# ESP32-C5 register map
Vendor: ESPRESSIF SYSTEMS (SHANGHAI) CO., LTD.; Series: ESP32 C-Series; File version: 1
CPU: RV32IMAC r0p0, little endian, no MPU, no FPU, 0 interrupt priority bits
Address unit: 32 bits
Registers are 32-bit, read-write, reset 0x0 unless marked. A register's access mark holds for its fields unless they carry their own. Offsets are from the block's base; [hi:lo] are bit positions; {n}, {i} and the like mark numbered series.

## EFUSE — eFuse Controller
Base 0x600B4800
{0x0+4i} PGM_DATA{i} (i=0..7) — Represents pgm_data{i}
  [31:0] PGM_DATA — Configures the %sth 32-bit data to be programmed.
{0x20+4i} PGM_CHECK_VALUE{i} (i=0..2) — Represents pgm_check_value{i}
  [31:0] PGM_RS_DATA — Configures the %sth RS code to be programmed.
0x2C RD_WR_DIS0 ro — Represents rd_wr_dis
  [31:0] WR_DIS — Represents whether programming of individual eFuse memory bit is disabled or enabled.\\ 1: Disabled\\ 0: Enabled\\
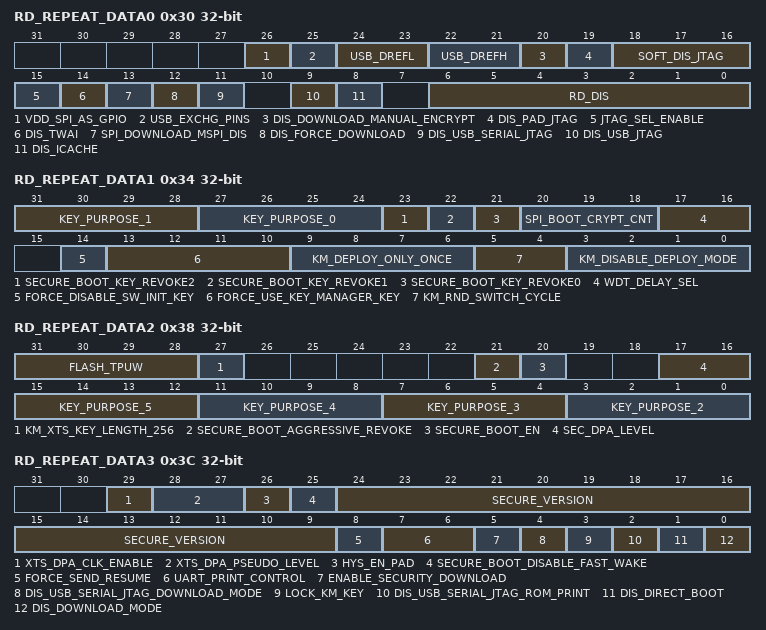
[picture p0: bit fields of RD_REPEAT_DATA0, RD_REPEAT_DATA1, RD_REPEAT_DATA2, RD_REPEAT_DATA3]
0x30 RD_REPEAT_DATA0 ro — Represents rd_repeat_data
  [26] VDD_SPI_AS_GPIO — Represents whether vdd spi pin is functioned as gpio.\\ 1: functioned\\ 0: not functioned\\
  [25] USB_EXCHG_PINS — Represents whether the D+ and D- pins is exchanged.\\ 1: exchanged\\ 0: not exchanged\\
  [24:23] USB_DREFL — Represents the single-end input threhold vrefl, 1.76 V to 2 V with step of 80 mV.
  [22:21] USB_DREFH — Represents the single-end input threhold vrefh, 1.76 V to 2 V with step of 80 mV.
  [20] DIS_DOWNLOAD_MANUAL_ENCRYPT — Represents whether flash encrypt function is disabled or enabled(except in SPI boot mode).\\ 1: disabled\\ 0: enabled\\
  [19] DIS_PAD_JTAG — Represents whether JTAG is disabled in the hard way(permanently).\\ 1: disabled\\ 0: enabled\\
  [18:16] SOFT_DIS_JTAG — Represents whether JTAG is disabled in soft way.\\ Odd number: disabled\\ Even number: enabled\\
  [15] JTAG_SEL_ENABLE — Represents whether the selection between usb_to_jtag and pad_to_jtag through strapping gpio15 when both EFUSE_DIS_PAD_JTAG and EFUSE_DIS_USB_JTAG are equal to 0 is enabled or disabled.\\ 1: enabled\\ 0: disabled\\
  [14] DIS_TWAI — Represents whether TWAI function is disabled or enabled.\\ 1: disabled\\ 0: enabled\\
  [13] SPI_DOWNLOAD_MSPI_DIS — Represents whether SPI0 controller during boot_mode_download is disabled or enabled.\\ 1: disabled\\ 0: enabled\\
  [12] DIS_FORCE_DOWNLOAD — Represents whether the function that forces chip into download mode is disabled or enabled.\\ 1: disabled\\ 0: enabled\\
  [11] DIS_USB_SERIAL_JTAG — Represents whether USB-Serial-JTAG is disabled or enabled.\\ 1: disabled\\ 0: enabled\\
  [9] DIS_USB_JTAG — Represents whether the function of usb switch to jtag is disabled or enabled.\\ 1: disabled\\ 0: enabled\\
  [8] DIS_ICACHE — Represents whether icache is disabled or enabled.\\ 1: disabled\\ 0: enabled\\
  [6:0] RD_DIS — Represents whether reading of individual eFuse block(block4~block10) is disabled or enabled.\\ 1: disabled\\ 0: enabled\\
0x34 RD_REPEAT_DATA1 ro — Represents rd_repeat_data
  [31:28] KEY_PURPOSE_1 — Represents the purpose of Key1.
  [27:24] KEY_PURPOSE_0 — Represents the purpose of Key0.
  [23] SECURE_BOOT_KEY_REVOKE2 — Represents whether revoking third secure boot key is enabled or disabled.\\ 1: enabled\\ 0: disabled\\
  [22] SECURE_BOOT_KEY_REVOKE1 — Represents whether revoking second secure boot key is enabled or disabled.\\ 1: enabled\\ 0: disabled\\
  [21] SECURE_BOOT_KEY_REVOKE0 — Represents whether revoking first secure boot key is enabled or disabled.\\ 1: enabled\\ 0: disabled\\
  [20:18] SPI_BOOT_CRYPT_CNT — Represents whether SPI boot encrypt/decrypt is disabled or enabled.\\ Odd number of 1: enabled\\ Even number of 1: disabled\\
  [17:16] WDT_DELAY_SEL — Represents the threshold level of the RTC watchdog STG0 timeout.\\ 0: Original threshold configuration value of STG0 *2 \\1: Original threshold configuration value of STG0 *4 \\2: Original threshold configuration value of STG0 *8 \\3: Original threshold configuration value of STG0 *16 \\
  [14] FORCE_DISABLE_SW_INIT_KEY — Set this bit to disable software written init key, and force use efuse_init_key.
  [13:10] FORCE_USE_KEY_MANAGER_KEY — Set each bit to control whether corresponding key must come from key manager. 1 is true, 0 is false. bit 0: ecsda, bit 1: xts, bit2: hmac, bit3: ds
  [9:6] KM_DEPLOY_ONLY_ONCE — Set each bit to control whether corresponding key can only be deployed once. 1 is true, 0 is false. bit 0: ecsda, bit 1: xts, bit2: hmac, bit3: ds
  [5:4] KM_RND_SWITCH_CYCLE — Set the bits to control key manager random number switch cycle. 0: control by register. 1: 8 km clk cycles. 2: 16 km cycles. 3: 32 km cycles
  [3:0] KM_DISABLE_DEPLOY_MODE — Represents whether the deploy mode of key manager is disable or not. \\ 1: disabled \\ 0: enabled.\\
0x38 RD_REPEAT_DATA2 ro — Represents rd_repeat_data
  [31:28] FLASH_TPUW — Represents the flash waiting time after power-up, in unit of ms. When the value less than 15, the waiting time is the programmed value. Otherwise, the waiting time is 2 times the programmed value.
  [27] KM_XTS_KEY_LENGTH_256 — Set this bitto configure flash encryption use xts-128 key. else use xts-256 key.
  [21] SECURE_BOOT_AGGRESSIVE_REVOKE — Represents whether revoking aggressive secure boot is enabled or disabled.\\ 1: enabled.\\ 0: disabled\\
  [20] SECURE_BOOT_EN — Represents whether secure boot is enabled or disabled.\\ 1: enabled\\ 0: disabled\\
  [17:16] SEC_DPA_LEVEL — Represents the spa secure level by configuring the clock random divide mode.
  [4n-5:4n-8] KEY_PURPOSE_{n} (n=2..5) — Represents the purpose of Key{n}.
0x3C RD_REPEAT_DATA3 ro — Represents rd_repeat_data
  [29] XTS_DPA_CLK_ENABLE — Represents whether xts-aes anti-dpa attack clock is enabled.\\ 1. Enable.\\ 0: Disable.\\
  [28:27] XTS_DPA_PSEUDO_LEVEL — Represents the pseudo round level of xts-aes anti-dpa attack.\\ 3: High.\\ 2: Moderate 1. Low\\ 0: Disabled\\
  [26] HYS_EN_PAD — Represents whether the hysteresis function of corresponding PAD is enabled.\\ 1: enabled\\ 0:disabled\\
  [25] SECURE_BOOT_DISABLE_FAST_WAKE — Represents whether FAST VERIFY ON WAKE is disabled or enabled when Secure Boot is enabled.\\ 1: disabled\\ 0: enabled\\
  [24:9] SECURE_VERSION — Represents the version used by ESP-IDF anti-rollback feature.
  [8] FORCE_SEND_RESUME — Represents whether ROM code is forced to send a resume command during SPI boot.\\ 1: forced\\ 0:not forced\\
  [7:6] UART_PRINT_CONTROL — Represents the type of UART printing.\\ 00: force enable printing\\ 01: enable printing when GPIO8 is reset at low level\\ 10: enable printing when GPIO8 is reset at high level\\ 11: force disable printing\\
  [5] ENABLE_SECURITY_DOWNLOAD — Represents whether security download is enabled or disabled.\\ 1: enabled\\ 0: disabled\\
  [4] DIS_USB_SERIAL_JTAG_DOWNLOAD_MODE — Represents whether the USB-Serial-JTAG download function is disabled or enabled.\\ 1: Disable\\ 0: Enable\\
  [3] LOCK_KM_KEY — Represetns whether to lock the efuse xts key.\\ 1. Lock\\ 0: Unlock\\
  [2] DIS_USB_SERIAL_JTAG_ROM_PRINT — Represents whether print from USB-Serial-JTAG is disabled or enabled.\\ 1: disabled\\ 0: enabled\\
  [1] DIS_DIRECT_BOOT — Represents whether direct boot mode is disabled or enabled.\\ 1: disabled\\ 0: enabled\\
  [0] DIS_DOWNLOAD_MODE — Represents whether Download mode is disabled or enabled.\\ 1: disabled\\ 0: enabled\\
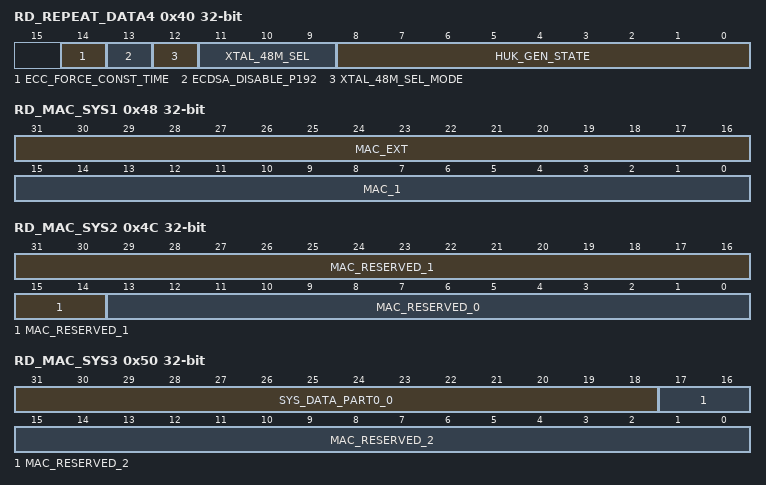
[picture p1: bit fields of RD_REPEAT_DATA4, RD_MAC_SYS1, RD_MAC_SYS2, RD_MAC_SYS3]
0x40 RD_REPEAT_DATA4 ro — Represents rd_repeat_data
  [14] ECC_FORCE_CONST_TIME — Represents whether to force ecc to use const-time calculation mode. \\ 1: Enable. \\ 0: Disable.
  [13] ECDSA_DISABLE_P192 — Represents whether to disable P192 curve in ECDSA.\\ 1: Disabled.\\ 0: Not disable.
  [12] XTAL_48M_SEL_MODE — Specify the XTAL frequency selection is decided by eFuse or strapping-PAD-state. 1: eFuse\\ 0: strapping-PAD-state.
  [11:9] XTAL_48M_SEL — Represents whether XTAL frequency is 48MHz or not. If not, 40MHz XTAL will be used. If this field contains Odd number bit '1': Enable 48MHz XTAL\\ Even number bit '1': Enable 40MHz XTAL.
  [8:0] HUK_GEN_STATE — Set the bits to control validation of HUK generate mode.\\ Odd of 1 is invalid.\\ Even of 1 is valid.\\
0x44 RD_MAC_SYS0 ro — Represents rd_mac_sys
  [31:0] MAC_0 — Represents MAC address. Low 32-bit.
0x48 RD_MAC_SYS1 ro — Represents rd_mac_sys
  [31:16] MAC_EXT — Represents the extended bits of MAC address.
  [15:0] MAC_1 — Represents MAC address. High 16-bit.
0x4C RD_MAC_SYS2 ro — Represents rd_mac_sys
  [31:14] MAC_RESERVED_1 — Reserved.
  [13:0] MAC_RESERVED_0 — Reserved.
0x50 RD_MAC_SYS3 ro — Represents rd_mac_sys
  [31:18] SYS_DATA_PART0_0 — Represents the first 14-bit of zeroth part of system data.
  [17:0] MAC_RESERVED_2 — Reserved.
0x54 RD_MAC_SYS4 ro — Represents rd_mac_sys
  [31:0] SYS_DATA_PART0_1 — Represents the first 14-bit of zeroth part of system data.
0x58 RD_MAC_SYS5 ro — Represents rd_mac_sys
  [31:0] SYS_DATA_PART0_2 — Represents the second 32-bit of zeroth part of system data.
{0x5C+4i} RD_SYS_PART1_DATA{i} (i=0..7) ro — Represents rd_sys_part1_data{i}
  [31:0] SYS_DATA_PART1 — Represents the zeroth 32-bit of first part of system data.
{0x7C+4i} RD_USR_DATA{i} (i=0..7) ro — Represents rd_usr_data{i}
  [31:0] USR_DATA — Represents the zeroth 32-bit of block3 (user).
{0x9C+4i} RD_KEY0_DATA{i} (i=0..7) ro — Represents rd_key0_data{i}
  [31:0] KEY0_DATA — Represents the zeroth 32-bit of key0.
{0xBC+4i} RD_KEY1_DATA{i} (i=0..7) ro — Represents rd_key1_data{i}
  [31:0] KEY1_DATA — Represents the zeroth 32-bit of key1.
{0xDC+4i} RD_KEY2_DATA{i} (i=0..7) ro — Represents rd_key2_data{i}
  [31:0] KEY2_DATA — Represents the zeroth 32-bit of key2.
{0xFC+4i} RD_KEY3_DATA{i} (i=0..7) ro — Represents rd_key3_data{i}
  [31:0] KEY3_DATA — Represents the zeroth 32-bit of key3.
{0x11C+4i} RD_KEY4_DATA{i} (i=0..7) ro — Represents rd_key4_data{i}
  [31:0] KEY4_DATA — Represents the zeroth 32-bit of key4.
{0x13C+4i} RD_KEY5_DATA{i} (i=0..7) ro — Represents rd_key5_data{i}
  [31:0] KEY5_DATA — Represents the zeroth 32-bit of key5.
{0x15C+4i} RD_SYS_PART2_DATA{i} (i=0..7) ro — Represents rd_sys_part2_data{i}
  [31:0] SYS_DATA_PART2 — Represents the zeroth 32-bit of second part of system data.
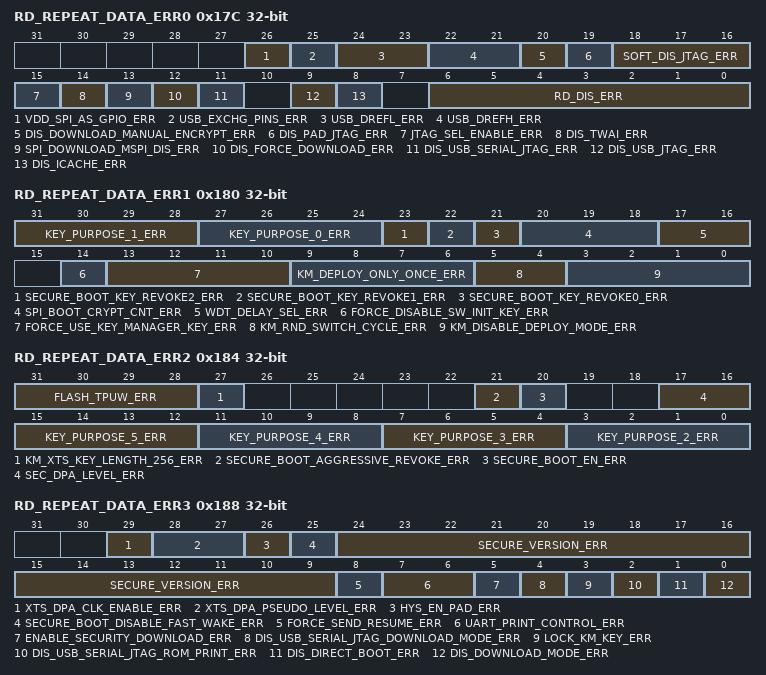
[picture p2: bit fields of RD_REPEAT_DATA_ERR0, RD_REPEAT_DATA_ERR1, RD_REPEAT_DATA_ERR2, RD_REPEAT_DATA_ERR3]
0x17C RD_REPEAT_DATA_ERR0 ro — Represents rd_repeat_data_err
  [26] VDD_SPI_AS_GPIO_ERR — Represents the programming error of EFUSE_VDD_SPI_AS_GPIO
  [25] USB_EXCHG_PINS_ERR — Represents the programming error of EFUSE_USB_EXCHG_PINS
  [24:23] USB_DREFL_ERR — Represents the programming error of EFUSE_USB_DREFL
  [22:21] USB_DREFH_ERR — Represents the programming error of EFUSE_USB_DREFH
  [20] DIS_DOWNLOAD_MANUAL_ENCRYPT_ERR — Represents the programming error of EFUSE_DIS_DOWNLOAD_MANUAL_ENCRYPT
  [19] DIS_PAD_JTAG_ERR — Represents the programming error of EFUSE_DIS_PAD_JTAG
  [18:16] SOFT_DIS_JTAG_ERR — Represents the programming error of EFUSE_SOFT_DIS_JTAG
  [15] JTAG_SEL_ENABLE_ERR — Represents the programming error of EFUSE_JTAG_SEL_ENABLE
  [14] DIS_TWAI_ERR — Represents the programming error of EFUSE_DIS_TWAI
  [13] SPI_DOWNLOAD_MSPI_DIS_ERR — Represents the programming error of EFUSE_SPI_DOWNLOAD_MSPI_DIS
  [12] DIS_FORCE_DOWNLOAD_ERR — Represents the programming error of EFUSE_DIS_FORCE_DOWNLOAD
  [11] DIS_USB_SERIAL_JTAG_ERR — Represents the programming error of EFUSE_DIS_USB_SERIAL_JTAG
  [9] DIS_USB_JTAG_ERR — Represents the programming error of EFUSE_DIS_USB_JTAG
  [8] DIS_ICACHE_ERR — Represents the programming error of EFUSE_DIS_ICACHE
  [6:0] RD_DIS_ERR — Represents the programming error of EFUSE_RD_DIS
0x180 RD_REPEAT_DATA_ERR1 ro — Represents rd_repeat_data_err
  [31:28] KEY_PURPOSE_1_ERR — Represents the programming error of EFUSE_KEY_PURPOSE_1
  [27:24] KEY_PURPOSE_0_ERR — Represents the programming error of EFUSE_KEY_PURPOSE_0
  [23] SECURE_BOOT_KEY_REVOKE2_ERR — Represents the programming error of EFUSE_SECURE_BOOT_KEY_REVOKE2
  [22] SECURE_BOOT_KEY_REVOKE1_ERR — Represents the programming error of EFUSE_SECURE_BOOT_KEY_REVOKE1
  [21] SECURE_BOOT_KEY_REVOKE0_ERR — Represents the programming error of EFUSE_SECURE_BOOT_KEY_REVOKE0
  [20:18] SPI_BOOT_CRYPT_CNT_ERR — Represents the programming error of EFUSE_SPI_BOOT_CRYPT_CNT
  [17:16] WDT_DELAY_SEL_ERR — Represents the programming error of EFUSE_WDT_DELAY_SEL
  [14] FORCE_DISABLE_SW_INIT_KEY_ERR — Represents the programming error of EFUSE_FORCE_DISABLE_SW_INIT_KEY
  [13:10] FORCE_USE_KEY_MANAGER_KEY_ERR — Represents the programming error of EFUSE_FORCE_USE_KEY_MANAGER_KEY
  [9:6] KM_DEPLOY_ONLY_ONCE_ERR — Represents the programming error of EFUSE_KM_DEPLOY_ONLY_ONCE
  [5:4] KM_RND_SWITCH_CYCLE_ERR — Represents the programming error of EFUSE_KM_RND_SWITCH_CYCLE
  [3:0] KM_DISABLE_DEPLOY_MODE_ERR — Represents the programming error of EFUSE_KM_DISABLE_DEPLOY_MODE
0x184 RD_REPEAT_DATA_ERR2 ro — Represents rd_repeat_data_err
  [31:28] FLASH_TPUW_ERR — Represents the programming error of EFUSE_FLASH_TPUW
  [27] KM_XTS_KEY_LENGTH_256_ERR — Represents the programming error of EFUSE_KM_XTS_KEY_LENGTH_256
  [21] SECURE_BOOT_AGGRESSIVE_REVOKE_ERR — Represents the programming error of EFUSE_SECURE_BOOT_AGGRESSIVE_REVOKE
  [20] SECURE_BOOT_EN_ERR — Represents the programming error of EFUSE_SECURE_BOOT_EN
  [17:16] SEC_DPA_LEVEL_ERR — Represents the programming error of EFUSE_SEC_DPA_LEVEL
  [4n-5:4n-8] KEY_PURPOSE_{n}_ERR (n=2..5) — Represents the programming error of EFUSE_KEY_PURPOSE_{n}
0x188 RD_REPEAT_DATA_ERR3 ro — Represents rd_repeat_data_err
  [29] XTS_DPA_CLK_ENABLE_ERR — Represents the programming error of EFUSE_XTS_DPA_CLK_ENABLE
  [28:27] XTS_DPA_PSEUDO_LEVEL_ERR — Represents the programming error of EFUSE_XTS_DPA_PSEUDO_LEVEL
  [26] HYS_EN_PAD_ERR — Represents the programming error of EFUSE_HYS_EN_PAD
  [25] SECURE_BOOT_DISABLE_FAST_WAKE_ERR — Represents the programming error of EFUSE_SECURE_BOOT_DISABLE_FAST_WAKE
  [24:9] SECURE_VERSION_ERR — Represents the programming error of EFUSE_SECURE_VERSION
  [8] FORCE_SEND_RESUME_ERR — Represents the programming error of EFUSE_FORCE_SEND_RESUME
  [7:6] UART_PRINT_CONTROL_ERR — Represents the programming error of EFUSE_UART_PRINT_CONTROL
  [5] ENABLE_SECURITY_DOWNLOAD_ERR — Represents the programming error of EFUSE_ENABLE_SECURITY_DOWNLOAD
  [4] DIS_USB_SERIAL_JTAG_DOWNLOAD_MODE_ERR — Represents the programming error of EFUSE_DIS_USB_SERIAL_JTAG_DOWNLOAD_MODE
  [3] LOCK_KM_KEY_ERR — Represents the programming error of EFUSE_LOCK_KM_KEY
  [2] DIS_USB_SERIAL_JTAG_ROM_PRINT_ERR — Represents the programming error of EFUSE_DIS_USB_SERIAL_JTAG_ROM_PRINT
  [1] DIS_DIRECT_BOOT_ERR — Represents the programming error of EFUSE_DIS_DIRECT_BOOT
  [0] DIS_DOWNLOAD_MODE_ERR — Represents the programming error of EFUSE_DIS_DOWNLOAD_MODE
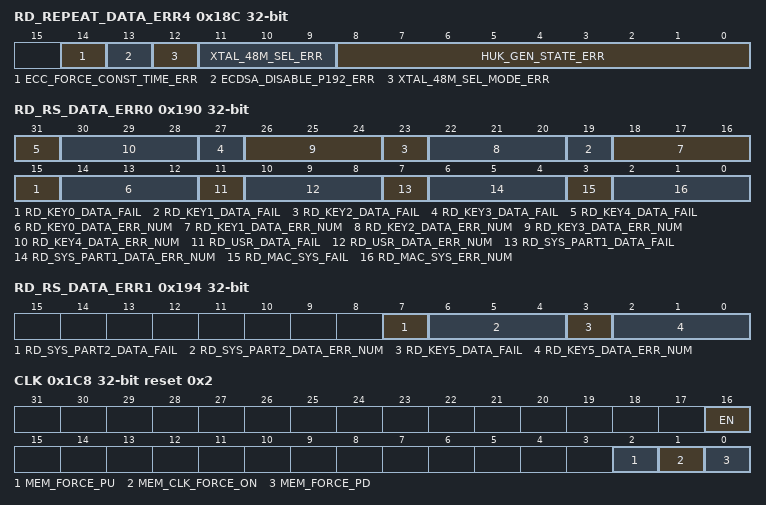
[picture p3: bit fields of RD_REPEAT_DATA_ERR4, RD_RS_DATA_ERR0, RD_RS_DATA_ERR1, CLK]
0x18C RD_REPEAT_DATA_ERR4 ro — Represents rd_repeat_data_err
  [14] ECC_FORCE_CONST_TIME_ERR — Represents the programming error of EFUSE_ECC_FORCE_CONST_TIME
  [13] ECDSA_DISABLE_P192_ERR — Represents the programming error of EFUSE_ECDSA_DISABLE_P192
  [12] XTAL_48M_SEL_MODE_ERR — Represents the programming error of EFUSE_XTAL_48M_SEL_MODE
  [11:9] XTAL_48M_SEL_ERR — Represents the programming error of EFUSE_XTAL_48M_SEL
  [8:0] HUK_GEN_STATE_ERR — Represents the programming error of EFUSE_HUK_GEN_STATE
0x190 RD_RS_DATA_ERR0 ro — Represents rd_rs_data_err
  [4n+15] RD_KEY{n}_DATA_FAIL (n=0..4) — Represents error status of register.\\0: Means no failure and that the data of rd_key{n}_data is reliable\\ 1: Means that programming rd_key{n}_data failed and the number of error bytes is over 6.
  [4n+14:4n+12] RD_KEY{n}_DATA_ERR_NUM (n=0..4) — Represents the error number of registers.\\The value of this signal means the number of error bytes in rd_key{n}_data
  [11] RD_USR_DATA_FAIL — Represents error status of register.\\0: Means no failure and that the data of rd_usr_data is reliable\\ 1: Means that programming rd_usr_data failed and the number of error bytes is over 6.
  [10:8] RD_USR_DATA_ERR_NUM — Represents the error number of registers.\\The value of this signal means the number of error bytes in rd_usr_data
  [7] RD_SYS_PART1_DATA_FAIL — Represents error status of register.\\0: Means no failure and that the data of rd_sys_part1_data is reliable\\ 1: Means that programming rd_sys_part1_data failed and the number of error bytes is over 6.
  [6:4] RD_SYS_PART1_DATA_ERR_NUM — Represents the error number of registers.\\The value of this signal means the number of error bytes in rd_sys_part1_data
  [3] RD_MAC_SYS_FAIL — Represents error status of register.\\0: Means no failure and that the data of rd_mac_sys is reliable\\ 1: Means that programming rd_mac_sys failed and the number of error bytes is over 6.
  [2:0] RD_MAC_SYS_ERR_NUM — Represents the error number of registers.\\The value of this signal means the number of error bytes in rd_mac_sys
0x194 RD_RS_DATA_ERR1 ro — Represents rd_rs_data_err
  [7] RD_SYS_PART2_DATA_FAIL — Represents error status of register.\\0: Means no failure and that the data of rd_sys_part2_data is reliable\\ 1: Means that programming rd_sys_part2_data failed and the number of error bytes is over 6.
  [6:4] RD_SYS_PART2_DATA_ERR_NUM — Represents the error number of registers.\\The value of this signal means the number of error bytes in rd_sys_part2_data
  [3] RD_KEY5_DATA_FAIL — Represents error status of register.\\0: Means no failure and that the data of rd_key5_data is reliable\\ 1: Means that programming rd_key5_data failed and the number of error bytes is over 6.
  [2:0] RD_KEY5_DATA_ERR_NUM — Represents the error number of registers.\\The value of this signal means the number of error bytes in rd_key5_data
0x198 DATE reset 0x2401080 — eFuse version register.
  [27:0] DATE — Stores eFuse version.
0x1C8 CLK reset 0x2 — eFuse clcok configuration register.
  [16] EN — Set this bit to force enable eFuse register configuration clock signal.
  [2] MEM_FORCE_PU — Set this bit to force eFuse SRAM into working mode.
  [1] MEM_CLK_FORCE_ON — Set this bit and force to activate clock signal of eFuse SRAM.
  [0] MEM_FORCE_PD — Set this bit to force eFuse SRAM into power-saving mode.
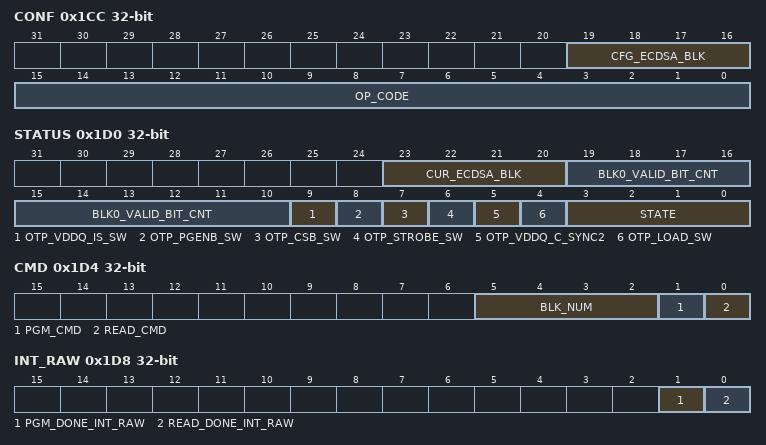
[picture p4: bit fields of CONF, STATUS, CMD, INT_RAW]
0x1CC CONF — eFuse operation mode configuraiton register
  [19:16] CFG_ECDSA_BLK — Configures which block to use for ECDSA key output.
  [15:0] OP_CODE — 0x5A5A: programming operation command 0x5AA5: read operation command.
0x1D0 STATUS ro — eFuse status register.
  [23:20] CUR_ECDSA_BLK — Indicates which block is used for ECDSA key output.
  [19:10] BLK0_VALID_BIT_CNT — Indicates the number of block valid bit.
  [9] OTP_VDDQ_IS_SW — The value of OTP_VDDQ_IS_SW.
  [8] OTP_PGENB_SW — The value of OTP_PGENB_SW.
  [7] OTP_CSB_SW — The value of OTP_CSB_SW.
  [6] OTP_STROBE_SW — The value of OTP_STROBE_SW.
  [5] OTP_VDDQ_C_SYNC2 — The value of OTP_VDDQ_C_SYNC2.
  [4] OTP_LOAD_SW — The value of OTP_LOAD_SW.
  [3:0] STATE — Indicates the state of the eFuse state machine.
0x1D4 CMD — eFuse command register.
  [5:2] BLK_NUM — The serial number of the block to be programmed. Value 0-10 corresponds to block number 0-10, respectively.
  [1] PGM_CMD — Set this bit to send programming command.
  [0] READ_CMD — Set this bit to send read command.
0x1D8 INT_RAW ro — eFuse raw interrupt register.
  [1] PGM_DONE_INT_RAW — The raw bit signal for pgm_done interrupt.
  [0] READ_DONE_INT_RAW — The raw bit signal for read_done interrupt.
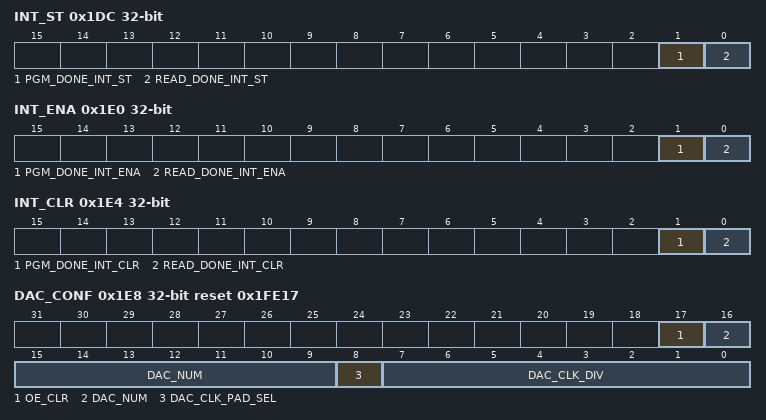
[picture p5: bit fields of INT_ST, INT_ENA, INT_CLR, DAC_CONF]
0x1DC INT_ST ro — eFuse interrupt status register.
  [1] PGM_DONE_INT_ST — The status signal for pgm_done interrupt.
  [0] READ_DONE_INT_ST — The status signal for read_done interrupt.
0x1E0 INT_ENA — eFuse interrupt enable register.
  [1] PGM_DONE_INT_ENA — The enable signal for pgm_done interrupt.
  [0] READ_DONE_INT_ENA — The enable signal for read_done interrupt.
0x1E4 INT_CLR wo — eFuse interrupt clear register.
  [1] PGM_DONE_INT_CLR — The clear signal for pgm_done interrupt.
  [0] READ_DONE_INT_CLR — The clear signal for read_done interrupt.
0x1E8 DAC_CONF reset 0x1FE17 — Controls the eFuse programming voltage.
  [17] OE_CLR — Reduces the power supply of the programming voltage.
  [16:9] DAC_NUM — Controls the rising period of the programming voltage.
  [8] DAC_CLK_PAD_SEL — Don't care.
  [7:0] DAC_CLK_DIV — Controls the division factor of the rising clock of the programming voltage.
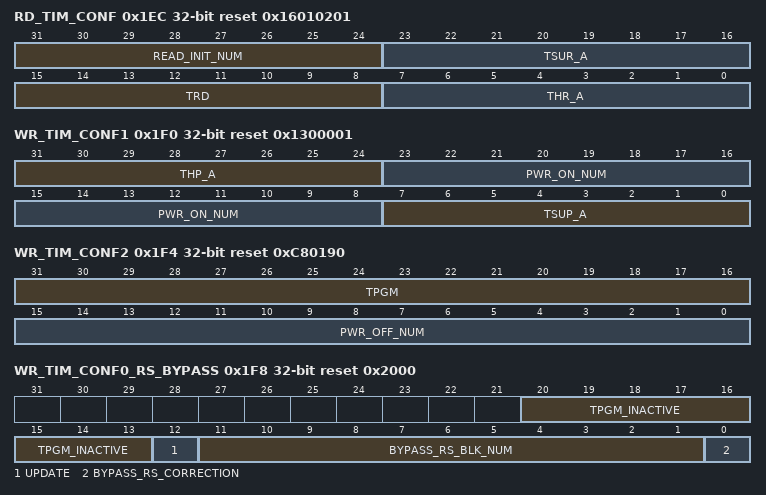
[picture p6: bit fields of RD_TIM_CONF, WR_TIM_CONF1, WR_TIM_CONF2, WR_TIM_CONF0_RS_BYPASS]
0x1EC RD_TIM_CONF reset 0x16010201 — Configures read timing parameters.
  [31:24] READ_INIT_NUM — Configures the waiting time of reading eFuse memory.
  [23:16] TSUR_A — Configures the read setup time.
  [15:8] TRD — Configures the read time.
  [7:0] THR_A — Configures the read hold time.
0x1F0 WR_TIM_CONF1 reset 0x1300001 — Configurarion register 1 of eFuse programming timing parameters.
  [31:24] THP_A — Configures the programming hold time.
  [23:8] PWR_ON_NUM — Configures the power up time for VDDQ.
  [7:0] TSUP_A — Configures the programming setup time.
0x1F4 WR_TIM_CONF2 reset 0xC80190 — Configurarion register 2 of eFuse programming timing parameters.
  [31:16] TPGM — Configures the active programming time.
  [15:0] PWR_OFF_NUM — Configures the power outage time for VDDQ.
0x1F8 WR_TIM_CONF0_RS_BYPASS access per field reset 0x2000 — Configurarion register0 of eFuse programming time parameters and rs bypass operation.
  [20:13] TPGM_INACTIVE rw — Configures the inactive programming time.
  [12] UPDATE wo — Set this bit to update multi-bit register signals.
  [11:1] BYPASS_RS_BLK_NUM rw — Configures block number of programming twice operation.
  [0] BYPASS_RS_CORRECTION rw — Set this bit to bypass reed solomon correction step.
0x500 APB2OTP_WR_DIS ro — eFuse apb2otp block0 data register1.
  [31:0] APB2OTP_BLOCK0_WR_DIS — Otp block0 write disable data.
{0x500+4i} APB2OTP_BLK0_BACKUP1_W{i} ro (i=1..5) — eFuse apb2otp block0 data register{i+1}.
  [31:0] APB2OTP_BLOCK0_BACKUP1_W{i} — Otp block0 backup1 word{i} data.
{0x514+4i} APB2OTP_BLK0_BACKUP2_W{i} ro (i=1..5) — eFuse apb2otp block0 data register{i+6}.
  [31:0] APB2OTP_BLOCK0_BACKUP2_W{i} — Otp block0 backup2 word{i} data.
{0x528+4i} APB2OTP_BLK0_BACKUP3_W{i} ro (i=1..5) — eFuse apb2otp block0 data register{i+11}.
  [31:0] APB2OTP_BLOCK0_BACKUP3_W{i} — Otp block0 backup3 word{i} data.
{0x53C+4i} APB2OTP_BLK0_BACKUP4_W{i} ro (i=1..5) — eFuse apb2otp block0 data register{i+16}.
  [31:0] APB2OTP_BLOCK0_BACKUP4_W{i} — Otp block0 backup4 word{i} data.
{0x550+4i} APB2OTP_BLK1_W{i} ro (i=1..9) — eFuse apb2otp block1 data register{i}.
  [31:0] APB2OTP_BLOCK1_W{i} — Otp block1 word{i} data.
{0x574+4i} APB2OTP_BLK2_W{i} ro (i=1..11) — eFuse apb2otp block2 data register{i}.
  [31:0] APB2OTP_BLOCK2_W{i} — Otp block2 word{i} data.
{0x5A0+4i} APB2OTP_BLK3_W{i} ro (i=1..11) — eFuse apb2otp block3 data register{i}.
  [31:0] APB2OTP_BLOCK3_W{i} — Otp block3 word{i} data.
0x5D0 APB2OTP_BLK4_W1 ro — eFuse apb2otp BLOCK7 data register1.
  [31:0] APB2OTP_BLOCK4_W1 — Otp block4 word1 data.
{0x5CC+4i} APB2OTP_BLK4_W{i} ro (i=2..9) — eFuse apb2otp block4 data register{i}.
  [31:0] APB2OTP_BLOCK4_W{i} — Otp block4 word{i} data.
0x5F4 APB2OTP_BLK4_W10 ro — eFuse apb2otp block4 data registe10.
  [31:0] APB2OTP_BLOCK4_W10 — Otp block4 word10 data.
0x5F8 APB2OTP_BLK4_W11 ro — eFuse apb2otp block4 data register11.
  [31:0] APB2OTP_BLOCK4_W11 — Otp block4 word11 data.
{0x5F8+4i} APB2OTP_BLK5_W{i} ro (i=1..11) — eFuse apb2otp block5 data register{i}.
  [31:0] APB2OTP_BLOCK5_W{i} — Otp block5 word{i} data.
{0x624+4i} APB2OTP_BLK6_W{i} ro (i=1..11) — eFuse apb2otp block6 data register{i}.
  [31:0] APB2OTP_BLOCK6_W{i} — Otp block6 word{i} data.
{0x650+4i} APB2OTP_BLK7_W{i} ro (i=1..11) — eFuse apb2otp block7 data register{i}.
  [31:0] APB2OTP_BLOCK7_W{i} — Otp block7 word{i} data.
{0x67C+4i} APB2OTP_BLK8_W{i} ro (i=1..11) — eFuse apb2otp block8 data register{i}.
  [31:0] APB2OTP_BLOCK8_W{i} — Otp block8 word{i} data.
{0x6A8+4i} APB2OTP_BLK9_W{i} ro (i=1..11) — eFuse apb2otp block9 data register{i}.
  [31:0] APB2OTP_BLOCK9_W{i} — Otp block9 word{i} data.
{0x6D4+4i} APB2OTP_BLK10_W{i} ro (i=1..11) — eFuse apb2otp block10 data register{i}.
  [31:0] APB2OTP_BLOCK10_W{i} — Otp block10 word{i} data.
0x708 APB2OTP_EN — eFuse apb2otp enable configuration register.
  [0] APB2OTP_APB2OTP_EN — Apb2otp mode enable signal.
